# YTM32B1HA0 register map
Vendor: YTMicro; File version: 1.0
CPU: little endian, MPU, FPU, 2 interrupt priority bits
Registers are 32-bit, read-write, reset 0x0 unless marked. A register's access mark holds for its fields unless they carry their own. Offsets are from the block's base; [hi:lo] are bit positions; {n}, {i} and the like mark numbered series.

## HCU — Hardware Cryptography Unit
Base 0x4019C000; register names take the prefix HCU_
0x00 GO
  [0] GO — Start Encryption/Decryption and indicate the module work state, write 0 to this bit is invalid.
    0=Encryption/Decryption idle; 1=Encryption/Decryption running
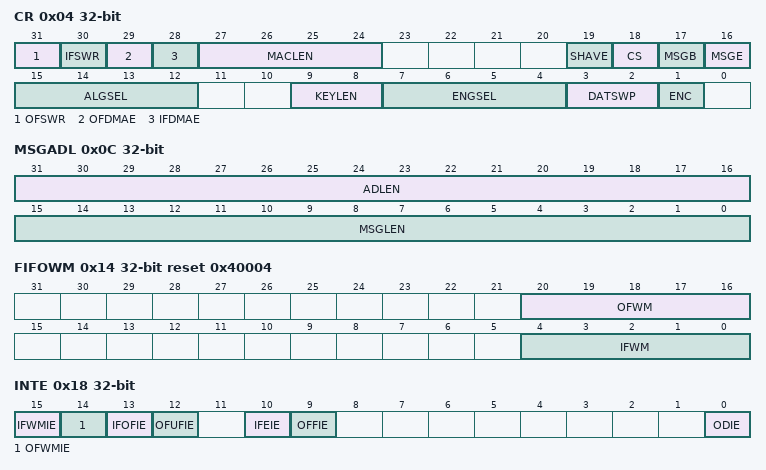
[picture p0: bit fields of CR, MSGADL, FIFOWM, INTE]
0x04 CR
  [31] OFSWR wo — Reset output FIFO, output FIFO data will be cleared, this bit is cleared automatic.
    0=Don't reset the output FIFO; 1=Reset the output FIFO
  [30] IFSWR wo — Reset input FIFO, input FIFO data will be cleared, this bit is cleared automatic.
    0=Don't reset the input FIFO; 1=Reset the input FIFO
  [29] OFDMAE — Output FIFO DMA enable/disable.
    0=Output FIFO DMA is disabled; 1=Output FIFO DMA is enabled
  [28] IFDMAE — Input FIFO DMA enable/disable.
    0=Input FIFO dma is disabled; 1=Input FIFO dma is enabled
  [27:24] MACLEN — MAC length for generation or validation.
    0=16 bytes; 1=1 byte; {v}={v} bytes (v=2..15)
  [19] SHAVE — SHA hash result verification enable/disable.
    0=SHA hash result verification is disable; 1=SHA hash result verification is enable
  [18] CS — Store the context data, for multiple message blocks process.
    0=Don't store context data; 1=Store context data
  [17] MSGB — Indicate the first message block, for multiple message blocks process.
    0=Current data block isn't the first block of the whole data; 1=Current data block is the first block of the whole data
  [16] MSGE — Indicate the last message block, for multiple message blocks process.
    0=Current data block isn't the last block of the whole data; 1=Current data block is the last block of the whole data
  [15:12] ALGSEL — Select algorithm for selected engine.
    0=AES-ECB/SM4-ECB/SHA-Reserved; 1=AES-CBC/SM4-Reserved/SHA-256; 2=AES-CTR/SM4-Reserved/SHA-384; 3=AES-CCM/SM4-Reserved/SHA-Reserved; 4=AES-CMAC/SM4-Reserved/SHA-Reserved
  [9:8] KEYLEN — Select key length for engine.
    0=128-bit; 1=192-bit; 2=256-bit
  [7:4] ENGSEL — Select engine for encryption/decryption.
    0=disable; 1=AES; 2=SM4; 3=SHA
  [3:2] DATSWP — Select the type of data swapping.
    0=No swap; 1=Half-word swapping; 2=Byte swapping; 3=Bit swapping
  [1] ENC — Select encryption or decryption mode.
    0=Decryption; 1=Encryption
0x08 MSGINFO
  [27:0] MSGTOT — Indicate byte number of message in total.
0x0C MSGADL
  [31:16] ADLEN — Indicate byte number of additional data in current block. Only [30:16] field is valid for AES engine.
  [15:0] MSGLEN — Indicate byte number of message in current block. Only [14:0] field is valid for AES engine.
0x14 FIFOWM reset 0x40004
  [20:16] OFWM — When the number of data in output FIFO is not less than the OFWM, interrupt or DMA request can be generated.
  [4:0] IFWM — When the number of data in input FIFO is less than the IFWM, interrupt or DMA request can be generated.
0x18 INTE
  [15] IFWMIE — Input FIFO watermark interrupt enable/disable.
    0=Input FIFO watermark interrupt disable; 1=Input FIFO watermark interrupt enable
  [14] OFWMIE — Output FIFO watermark interrupt enable/disable.
    0=Output FIFO watermark interrupt disable; 1=Output FIFO watermark interrupt enable
  [13] IFOFIE — Input FIFO overflow interrupt enable/disable.
    0=Input FIFO overflow interrupt disable; 1=Input FIFO overflow interrupt enable
  [12] OFUFIE — Output FIFO underflow interrupt enable/disable.
    0=Output FIFO underflow interrupt disable; 1=Output FIFO underflow interrupt enable
  [10] IFEIE — Input FIFO empty interrupt enable/disable.
    0=Input FIFO Empty interrupt disable; 1=Input FIFO empty interrupt enable
  [9] OFFIE — Output FIFO full interrupt enable/disable.
    0=Output FIFO full interrupt disable; 1=Output FIFO full interrupt enable
  [0] ODIE — Operation done interrupt enable/disable.
    0=Operation done interrupt disable; 1=Operation done interrupt enable
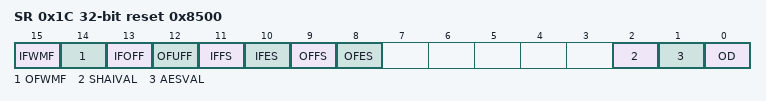
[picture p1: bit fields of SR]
0x1C SR reset 0x8500
  [15] IFWMF ro — Input FIFO watermark flag.
    0=Input FIFO watermark is not valid; 1=Input FIFO watermark is valid
  [14] OFWMF ro — Output FIFO watermark flag.
    0=Output FIFO watermark is not valid; 1=Output FIFO watermark is valid
  [13] IFOFF — Input FIFO overflow indicate. Write 1 to clear this bit.
    0=No input FIFO overflow detected; 1=Input FIFO overflow detected
  [12] OFUFF — Output FIFO underflow indicate. Write 1 to clear this bit.
    0=No output FIFO underflow detected; 1=Output FIFO underflow detected
  [11] IFFS ro — Indicate the input FIFO full state.
    0=Input FIFO is not full; 1=Input FIFO is full
  [10] IFES ro — Indicate the input FIFO empty state.
    0=Input FIFO is not empty; 1=Input FIFO is empty
  [9] OFFS ro — Indicate the output FIFO full state.
    0=Output FIFO is not full; 1=Output FIFO is full
  [8] OFES ro — Indicate the output FIFO empty state.
    0=Output FIFO is not empty; 1=Output FIFO is empty
  [2] SHAIVAL ro — Indicate the verify result of input hash value.
    0=Input hash value is equal to the calculate result; 1=Input hash value is not equal to the calculate result
  [1] AESVAL ro — Indicate AES MAC validation result.
    0=The input MAC is not equal to the calculate result; 1=The input MAC is equal to the calculate result
  [0] OD — Indicate Encryption/Decryption operation state. Write 1 to clear this bit.
    0=Operation doesn't begin or under running; 1=Operation done
{0x20+4i} KEY{i} wo (i=0..7)
  [31:0] KEY rw — Key value for Encryption/Decryption.
{0x50+4i} AESCV{i} (i=0..3)
  [31:0] CNT — Counter value for Encryption/Decryption.
{0x60+4i} AESIV{i} (i=0..3)
  [31:0] INIT — Initial vector value for Encryption/Decryption.
{0x70+4i} AESMAC{i} (i=0..3)
  [31:0] MAC — MAC value generated in Encryption or write for Decryption.
{0x80+4i} SHAICV{i} (i=0..11)
  [31:0] ICV — SHA input hash value for verification. Register 0~7 is used for SHA-256, register 0~11 is used for SHA-384.
0xB0 IFDAT wo
  [31:0] IFDAT rw — Input FIFO Data, write data that to be encrypted/decrypted. The data should be written in 128 bits.
0xB4 OFDAT ro
  [31:0] OFDAT rw — Output FIFO Data, read data that after encryption/decryption.
